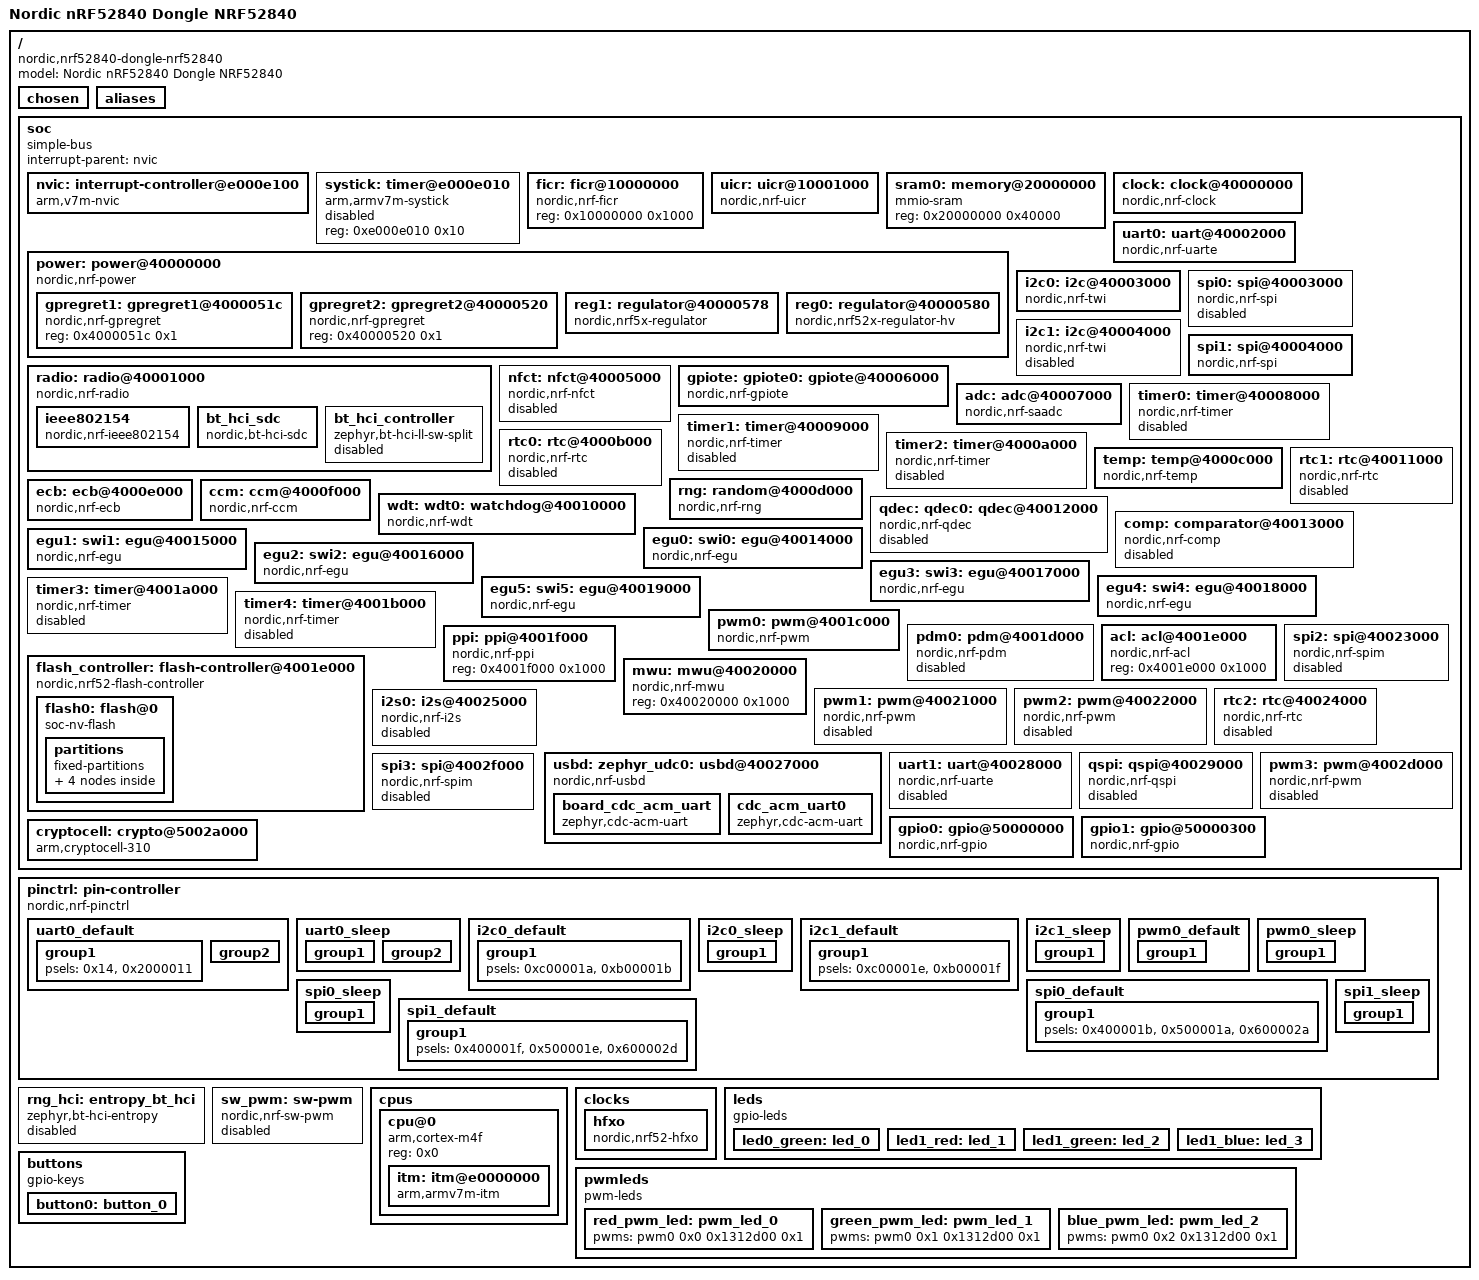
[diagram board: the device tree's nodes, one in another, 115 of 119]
/dts-v1/;

/* node '/' defined in zephyr\dts\common\skeleton.dtsi:9 */
/ {
	#address-cells = < 0x1 >;                       /* in zephyr\dts\common\skeleton.dtsi:10 */
	#size-cells = < 0x1 >;                          /* in zephyr\dts\common\skeleton.dtsi:11 */
	model = "Nordic nRF52840 Dongle NRF52840";      /* in zephyr\boards\nordic\nrf52840dongle\nrf52840dongle_nrf52840_common.dtsi:14 */
	compatible = "nordic,nrf52840-dongle-nrf52840"; /* in zephyr\boards\nordic\nrf52840dongle\nrf52840dongle_nrf52840_common.dtsi:15 */

	/* node '/chosen' defined in zephyr\dts\common\skeleton.dtsi:13 */
	chosen {
		zephyr,bt-hci = &bt_hci_sdc;                 /* in zephyr\dts\arm\nordic\nrf52840.dtsi:14 */
		zephyr,entropy = &cryptocell;                /* in zephyr\dts\arm\nordic\nrf52840.dtsi:15 */
		zephyr,flash-controller = &flash_controller; /* in zephyr\dts\arm\nordic\nrf52840.dtsi:16 */
		zephyr,sram = &sram0;                        /* in zephyr\boards\nordic\nrf52840dongle\nrf52840dongle_nrf52840_common.dtsi:18 */
		zephyr,flash = &flash0;                      /* in zephyr\boards\nordic\nrf52840dongle\nrf52840dongle_nrf52840_common.dtsi:19 */
		zephyr,code-partition = &slot0_partition;    /* in zephyr\boards\nordic\nrf52840dongle\nrf52840dongle_nrf52840_common.dtsi:20 */
		zephyr,ieee802154 = &ieee802154;             /* in zephyr\boards\nordic\nrf52840dongle\nrf52840dongle_nrf52840_common.dtsi:21 */
		zephyr,uart-mcumgr = &board_cdc_acm_uart;    /* in zephyr\boards\common\usb\cdc_acm_serial.dtsi:11 */
		zephyr,bt-mon-uart = &board_cdc_acm_uart;    /* in zephyr\boards\common\usb\cdc_acm_serial.dtsi:12 */
		zephyr,bt-c2h-uart = &board_cdc_acm_uart;    /* in zephyr\boards\common\usb\cdc_acm_serial.dtsi:13 */
		zephyr,console = &cdc_acm_uart0;             /* in nrf\samples\bluetooth\central_uart_test\app.overlay:3 */
		zephyr,shell-uart = &cdc_acm_uart0;          /* in nrf\samples\bluetooth\central_uart_test\app.overlay:4 */
	};

	/* node '/aliases' defined in zephyr\dts\common\skeleton.dtsi:15 */
	aliases {
		sw0 = &button0;                 /* in zephyr\boards\nordic\nrf52840dongle\nrf52840dongle_nrf52840_common.dtsi:76 */
		led0 = &led0_green;             /* in zephyr\boards\nordic\nrf52840dongle\nrf52840dongle_nrf52840_common.dtsi:77 */
		led1 = &led1_red;               /* in zephyr\boards\nordic\nrf52840dongle\nrf52840dongle_nrf52840_common.dtsi:78 */
		led2 = &led1_green;             /* in zephyr\boards\nordic\nrf52840dongle\nrf52840dongle_nrf52840_common.dtsi:79 */
		led3 = &led1_blue;              /* in zephyr\boards\nordic\nrf52840dongle\nrf52840dongle_nrf52840_common.dtsi:80 */
		led0-green = &led0_green;       /* in zephyr\boards\nordic\nrf52840dongle\nrf52840dongle_nrf52840_common.dtsi:81 */
		led1-red = &led1_red;           /* in zephyr\boards\nordic\nrf52840dongle\nrf52840dongle_nrf52840_common.dtsi:82 */
		led1-green = &led1_green;       /* in zephyr\boards\nordic\nrf52840dongle\nrf52840dongle_nrf52840_common.dtsi:83 */
		led1-blue = &led1_blue;         /* in zephyr\boards\nordic\nrf52840dongle\nrf52840dongle_nrf52840_common.dtsi:84 */
		pwm-led0 = &red_pwm_led;        /* in zephyr\boards\nordic\nrf52840dongle\nrf52840dongle_nrf52840_common.dtsi:85 */
		pwm-led1 = &green_pwm_led;      /* in zephyr\boards\nordic\nrf52840dongle\nrf52840dongle_nrf52840_common.dtsi:86 */
		pwm-led2 = &blue_pwm_led;       /* in zephyr\boards\nordic\nrf52840dongle\nrf52840dongle_nrf52840_common.dtsi:87 */
		red-pwm-led = &red_pwm_led;     /* in zephyr\boards\nordic\nrf52840dongle\nrf52840dongle_nrf52840_common.dtsi:88 */
		green-pwm-led = &green_pwm_led; /* in zephyr\boards\nordic\nrf52840dongle\nrf52840dongle_nrf52840_common.dtsi:89 */
		blue-pwm-led = &blue_pwm_led;   /* in zephyr\boards\nordic\nrf52840dongle\nrf52840dongle_nrf52840_common.dtsi:90 */
		mcuboot-button0 = &button0;     /* in zephyr\boards\nordic\nrf52840dongle\nrf52840dongle_nrf52840_common.dtsi:91 */
		mcuboot-led0 = &led0_green;     /* in zephyr\boards\nordic\nrf52840dongle\nrf52840dongle_nrf52840_common.dtsi:92 */
		watchdog0 = &wdt0;              /* in zephyr\boards\nordic\nrf52840dongle\nrf52840dongle_nrf52840_common.dtsi:93 */
	};

	/* node '/soc' defined in zephyr\dts\arm\armv7-m.dtsi:6 */
	soc {
		#address-cells = < 0x1 >;     /* in zephyr\dts\arm\armv7-m.dtsi:7 */
		#size-cells = < 0x1 >;        /* in zephyr\dts\arm\armv7-m.dtsi:8 */
		interrupt-parent = < &nvic >; /* in zephyr\dts\arm\armv7-m.dtsi:10 */
		ranges;                       /* in zephyr\dts\arm\armv7-m.dtsi:11 */
		compatible = "simple-bus";    /* in zephyr\dts\arm\nordic\nrf52840_qiaa.dtsi:30 */

		/* node '/soc/interrupt-controller@e000e100' defined in zephyr\dts\arm\armv7-m.dtsi:13 */
		nvic: interrupt-controller@e000e100 {
			#address-cells = < 0x1 >;            /* in zephyr\dts\arm\armv7-m.dtsi:14 */
			compatible = "arm,v7m-nvic";         /* in zephyr\dts\arm\armv7-m.dtsi:15 */
			reg = < 0xe000e100 0xc00 >;          /* in zephyr\dts\arm\armv7-m.dtsi:16 */
			interrupt-controller;                /* in zephyr\dts\arm\armv7-m.dtsi:17 */
			#interrupt-cells = < 0x2 >;          /* in zephyr\dts\arm\armv7-m.dtsi:18 */
			arm,num-irq-priority-bits = < 0x3 >; /* in zephyr\dts\arm\nordic\nrf52840.dtsi:590 */
			phandle = < 0x1 >;                   /* in zephyr\dts\arm\armv7-m.dtsi:10 */
		};

		/* node '/soc/timer@e000e010' defined in zephyr\dts\arm\armv7-m.dtsi:21 */
		systick: timer@e000e010 {
			compatible = "arm,armv7m-systick"; /* in zephyr\dts\arm\armv7-m.dtsi:22 */
			reg = < 0xe000e010 0x10 >;         /* in zephyr\dts\arm\armv7-m.dtsi:23 */
			status = "disabled";               /* in zephyr\dts\arm\nordic\nrf52840.dtsi:595 */
		};

		/* node '/soc/ficr@10000000' defined in zephyr\dts\arm\nordic\nrf52840.dtsi:48 */
		ficr: ficr@10000000 {
			compatible = "nordic,nrf-ficr"; /* in zephyr\dts\arm\nordic\nrf52840.dtsi:49 */
			reg = < 0x10000000 0x1000 >;    /* in zephyr\dts\arm\nordic\nrf52840.dtsi:50 */
			#nordic,ficr-cells = < 0x1 >;   /* in zephyr\dts\arm\nordic\nrf52840.dtsi:51 */
			status = "okay";                /* in zephyr\dts\arm\nordic\nrf52840.dtsi:52 */
		};

		/* node '/soc/uicr@10001000' defined in zephyr\dts\arm\nordic\nrf52840.dtsi:55 */
		uicr: uicr@10001000 {
			compatible = "nordic,nrf-uicr";     /* in zephyr\dts\arm\nordic\nrf52840.dtsi:56 */
			reg = < 0x10001000 0x1000 >;        /* in zephyr\dts\arm\nordic\nrf52840.dtsi:57 */
			ranges = < 0x0 0x10001000 0x1000 >; /* in zephyr\dts\arm\nordic\nrf52840.dtsi:58 */
			status = "okay";                    /* in zephyr\dts\arm\nordic\nrf52840.dtsi:59 */
			#address-cells = < 0x1 >;           /* in zephyr\dts\arm\nordic\nrf52840.dtsi:60 */
			#size-cells = < 0x1 >;              /* in zephyr\dts\arm\nordic\nrf52840.dtsi:61 */
			nfct-pins-as-gpios;                 /* in zephyr\boards\nordic\nrf52840dongle\nrf52840dongle_nrf52840_common.dtsi:114 */
			gpio-as-nreset;                     /* in zephyr\boards\nordic\nrf52840dongle\nrf52840dongle_nrf52840_common.dtsi:115 */
		};

		/* node '/soc/memory@20000000' defined in zephyr\dts\arm\nordic\nrf52840.dtsi:64 */
		sram0: memory@20000000 {
			compatible = "mmio-sram";            /* in zephyr\dts\arm\nordic\nrf52840.dtsi:65 */
			#address-cells = < 0x1 >;            /* in zephyr\dts\arm\nordic\nrf52840.dtsi:66 */
			#size-cells = < 0x1 >;               /* in zephyr\dts\arm\nordic\nrf52840.dtsi:67 */
			reg = < 0x20000000 0x40000 >;        /* in zephyr\dts\arm\nordic\nrf52840_qiaa.dtsi:15 */
			ranges = < 0x0 0x20000000 0x40000 >; /* in zephyr\dts\arm\nordic\nrf52840_qiaa.dtsi:16 */
		};

		/* node '/soc/clock@40000000' defined in zephyr\dts\arm\nordic\nrf52840.dtsi:70 */
		clock: clock@40000000 {
			compatible = "nordic,nrf-clock"; /* in zephyr\dts\arm\nordic\nrf52840.dtsi:71 */
			reg = < 0x40000000 0x1000 >;     /* in zephyr\dts\arm\nordic\nrf52840.dtsi:72 */
			interrupts = < 0x0 0x1 >;        /* in zephyr\dts\arm\nordic\nrf52840.dtsi:73 */
			status = "okay";                 /* in zephyr\dts\arm\nordic\nrf52840.dtsi:74 */
		};

		/* node '/soc/power@40000000' defined in zephyr\dts\arm\nordic\nrf52840.dtsi:77 */
		power: power@40000000 {
			compatible = "nordic,nrf-power"; /* in zephyr\dts\arm\nordic\nrf52840.dtsi:78 */
			reg = < 0x40000000 0x1000 >;     /* in zephyr\dts\arm\nordic\nrf52840.dtsi:79 */
			interrupts = < 0x0 0x1 >;        /* in zephyr\dts\arm\nordic\nrf52840.dtsi:80 */
			status = "okay";                 /* in zephyr\dts\arm\nordic\nrf52840.dtsi:81 */
			#address-cells = < 0x1 >;        /* in zephyr\dts\arm\nordic\nrf52840.dtsi:82 */
			#size-cells = < 0x1 >;           /* in zephyr\dts\arm\nordic\nrf52840.dtsi:83 */

			/* node '/soc/power@40000000/gpregret1@4000051c' defined in zephyr\dts\arm\nordic\nrf52840.dtsi:85 */
			gpregret1: gpregret1@4000051c {
				#address-cells = < 0x1 >;           /* in zephyr\dts\arm\nordic\nrf52840.dtsi:86 */
				#size-cells = < 0x1 >;              /* in zephyr\dts\arm\nordic\nrf52840.dtsi:87 */
				compatible = "nordic,nrf-gpregret"; /* in zephyr\dts\arm\nordic\nrf52840.dtsi:88 */
				reg = < 0x4000051c 0x1 >;           /* in zephyr\dts\arm\nordic\nrf52840.dtsi:89 */
				status = "okay";                    /* in zephyr\dts\arm\nordic\nrf52840.dtsi:90 */
			};

			/* node '/soc/power@40000000/gpregret2@40000520' defined in zephyr\dts\arm\nordic\nrf52840.dtsi:93 */
			gpregret2: gpregret2@40000520 {
				#address-cells = < 0x1 >;           /* in zephyr\dts\arm\nordic\nrf52840.dtsi:94 */
				#size-cells = < 0x1 >;              /* in zephyr\dts\arm\nordic\nrf52840.dtsi:95 */
				compatible = "nordic,nrf-gpregret"; /* in zephyr\dts\arm\nordic\nrf52840.dtsi:96 */
				reg = < 0x40000520 0x1 >;           /* in zephyr\dts\arm\nordic\nrf52840.dtsi:97 */
				status = "okay";                    /* in zephyr\dts\arm\nordic\nrf52840.dtsi:98 */
			};

			/* node '/soc/power@40000000/regulator@40000578' defined in zephyr\dts\arm\nordic\nrf52840.dtsi:101 */
			reg1: regulator@40000578 {
				compatible = "nordic,nrf5x-regulator"; /* in zephyr\dts\arm\nordic\nrf52840.dtsi:102 */
				reg = < 0x40000578 0x1 >;              /* in zephyr\dts\arm\nordic\nrf52840.dtsi:103 */
				regulator-name = "REG1";               /* in zephyr\dts\arm\nordic\nrf52840.dtsi:104 */
				regulator-initial-mode = < 0x1 >;      /* in zephyr\boards\nordic\nrf52840dongle\nrf52840dongle_nrf52840_common.dtsi:102 */
			};

			/* node '/soc/power@40000000/regulator@40000580' defined in zephyr\dts\arm\nordic\nrf52840_qiaa.dtsi:20 */
			reg0: regulator@40000580 {
				compatible = "nordic,nrf52x-regulator-hv"; /* in zephyr\dts\arm\nordic\nrf52840_qiaa.dtsi:21 */
				reg = < 0x40000580 0x1 >;                  /* in zephyr\dts\arm\nordic\nrf52840_qiaa.dtsi:22 */
				regulator-name = "REG0";                   /* in zephyr\dts\arm\nordic\nrf52840_qiaa.dtsi:23 */
				status = "okay";                           /* in zephyr\boards\nordic\nrf52840dongle\nrf52840dongle_nrf52840_common.dtsi:98 */
			};
		};

		/* node '/soc/radio@40001000' defined in zephyr\dts\arm\nordic\nrf52840.dtsi:109 */
		radio: radio@40001000 {
			compatible = "nordic,nrf-radio"; /* in zephyr\dts\arm\nordic\nrf52840.dtsi:110 */
			reg = < 0x40001000 0x1000 >;     /* in zephyr\dts\arm\nordic\nrf52840.dtsi:111 */
			interrupts = < 0x1 0x1 >;        /* in zephyr\dts\arm\nordic\nrf52840.dtsi:112 */
			status = "okay";                 /* in zephyr\dts\arm\nordic\nrf52840.dtsi:113 */
			ieee802154-supported;            /* in zephyr\dts\arm\nordic\nrf52840.dtsi:114 */
			ble-2mbps-supported;             /* in zephyr\dts\arm\nordic\nrf52840.dtsi:115 */
			ble-coded-phy-supported;         /* in zephyr\dts\arm\nordic\nrf52840.dtsi:116 */
			radio-tx-high-power-supported;   /* in zephyr\dts\arm\nordic\nrf52840.dtsi:117 */

			/* node '/soc/radio@40001000/ieee802154' defined in zephyr\dts\arm\nordic\nrf52840.dtsi:119 */
			ieee802154: ieee802154 {
				compatible = "nordic,nrf-ieee802154"; /* in zephyr\dts\arm\nordic\nrf52840.dtsi:120 */
				status = "okay";                      /* in zephyr\boards\nordic\nrf52840dongle\nrf52840dongle_nrf52840_common.dtsi:181 */
			};

			/* node '/soc/radio@40001000/bt_hci_sdc' defined in zephyr\dts\arm\nordic\nrf52840.dtsi:124 */
			bt_hci_sdc: bt_hci_sdc {
				compatible = "nordic,bt-hci-sdc"; /* in zephyr\dts\arm\nordic\nrf52840.dtsi:125 */
				status = "okay";                  /* in zephyr\dts\arm\nordic\nrf52840.dtsi:126 */
			};

			/* node '/soc/radio@40001000/bt_hci_controller' defined in zephyr\dts\arm\nordic\nrf52840.dtsi:128 */
			bt_hci_controller: bt_hci_controller {
				compatible = "zephyr,bt-hci-ll-sw-split"; /* in zephyr\dts\arm\nordic\nrf52840.dtsi:129 */
				status = "disabled";                      /* in zephyr\dts\arm\nordic\nrf52840.dtsi:130 */
			};
		};

		/* node '/soc/uart@40002000' defined in zephyr\dts\arm\nordic\nrf52840.dtsi:134 */
		uart0: uart@40002000 {
			reg = < 0x40002000 0x1000 >;     /* in zephyr\dts\arm\nordic\nrf52840.dtsi:138 */
			interrupts = < 0x2 0x1 >;        /* in zephyr\dts\arm\nordic\nrf52840.dtsi:139 */
			compatible = "nordic,nrf-uarte"; /* in zephyr\boards\nordic\nrf52840dongle\nrf52840dongle_nrf52840_common.dtsi:127 */
			status = "okay";                 /* in zephyr\boards\nordic\nrf52840dongle\nrf52840dongle_nrf52840_common.dtsi:128 */
			current-speed = < 0x1c200 >;     /* in zephyr\boards\nordic\nrf52840dongle\nrf52840dongle_nrf52840_common.dtsi:129 */
			pinctrl-0 = < &uart0_default >;  /* in zephyr\boards\nordic\nrf52840dongle\nrf52840dongle_nrf52840_common.dtsi:130 */
			pinctrl-1 = < &uart0_sleep >;    /* in zephyr\boards\nordic\nrf52840dongle\nrf52840dongle_nrf52840_common.dtsi:131 */
			pinctrl-names = "default",
			                "sleep";         /* in zephyr\boards\nordic\nrf52840dongle\nrf52840dongle_nrf52840_common.dtsi:132 */
		};

		/* node '/soc/i2c@40003000' defined in zephyr\dts\arm\nordic\nrf52840.dtsi:143 */
		i2c0: i2c@40003000 {
			#address-cells = < 0x1 >;       /* in zephyr\dts\arm\nordic\nrf52840.dtsi:152 */
			#size-cells = < 0x0 >;          /* in zephyr\dts\arm\nordic\nrf52840.dtsi:153 */
			reg = < 0x40003000 0x1000 >;    /* in zephyr\dts\arm\nordic\nrf52840.dtsi:154 */
			interrupts = < 0x3 0x1 >;       /* in zephyr\dts\arm\nordic\nrf52840.dtsi:155 */
			easydma-maxcnt-bits = < 0x10 >; /* in zephyr\dts\arm\nordic\nrf52840.dtsi:156 */
			zephyr,pm-device-runtime-auto;  /* in zephyr\dts\arm\nordic\nrf52840.dtsi:158 */
			compatible = "nordic,nrf-twi";  /* in zephyr\boards\nordic\nrf52840dongle\nrf52840dongle_nrf52840_common.dtsi:136 */
			status = "okay";                /* in zephyr\boards\nordic\nrf52840dongle\nrf52840dongle_nrf52840_common.dtsi:137 */
			pinctrl-0 = < &i2c0_default >;  /* in zephyr\boards\nordic\nrf52840dongle\nrf52840dongle_nrf52840_common.dtsi:138 */
			pinctrl-1 = < &i2c0_sleep >;    /* in zephyr\boards\nordic\nrf52840dongle\nrf52840dongle_nrf52840_common.dtsi:139 */
			pinctrl-names = "default",
			                "sleep";        /* in zephyr\boards\nordic\nrf52840dongle\nrf52840dongle_nrf52840_common.dtsi:140 */
		};

		/* node '/soc/spi@40003000' defined in zephyr\dts\arm\nordic\nrf52840.dtsi:161 */
		spi0: spi@40003000 {
			#address-cells = < 0x1 >;       /* in zephyr\dts\arm\nordic\nrf52840.dtsi:170 */
			#size-cells = < 0x0 >;          /* in zephyr\dts\arm\nordic\nrf52840.dtsi:171 */
			reg = < 0x40003000 0x1000 >;    /* in zephyr\dts\arm\nordic\nrf52840.dtsi:172 */
			interrupts = < 0x3 0x1 >;       /* in zephyr\dts\arm\nordic\nrf52840.dtsi:173 */
			max-frequency = < 0x7a1200 >;   /* in zephyr\dts\arm\nordic\nrf52840.dtsi:174 */
			easydma-maxcnt-bits = < 0x10 >; /* in zephyr\dts\arm\nordic\nrf52840.dtsi:175 */
			status = "disabled";            /* in zephyr\dts\arm\nordic\nrf52840.dtsi:176 */
			compatible = "nordic,nrf-spi";  /* in zephyr\boards\nordic\nrf52840dongle\nrf52840dongle_nrf52840_common.dtsi:164 */
			pinctrl-0 = < &spi0_default >;  /* in zephyr\boards\nordic\nrf52840dongle\nrf52840dongle_nrf52840_common.dtsi:167 */
			pinctrl-1 = < &spi0_sleep >;    /* in zephyr\boards\nordic\nrf52840dongle\nrf52840dongle_nrf52840_common.dtsi:168 */
			pinctrl-names = "default",
			                "sleep";        /* in zephyr\boards\nordic\nrf52840dongle\nrf52840dongle_nrf52840_common.dtsi:169 */
		};

		/* node '/soc/i2c@40004000' defined in zephyr\dts\arm\nordic\nrf52840.dtsi:179 */
		i2c1: i2c@40004000 {
			#address-cells = < 0x1 >;       /* in zephyr\dts\arm\nordic\nrf52840.dtsi:188 */
			#size-cells = < 0x0 >;          /* in zephyr\dts\arm\nordic\nrf52840.dtsi:189 */
			reg = < 0x40004000 0x1000 >;    /* in zephyr\dts\arm\nordic\nrf52840.dtsi:190 */
			interrupts = < 0x4 0x1 >;       /* in zephyr\dts\arm\nordic\nrf52840.dtsi:191 */
			easydma-maxcnt-bits = < 0x10 >; /* in zephyr\dts\arm\nordic\nrf52840.dtsi:192 */
			status = "disabled";            /* in zephyr\dts\arm\nordic\nrf52840.dtsi:193 */
			zephyr,pm-device-runtime-auto;  /* in zephyr\dts\arm\nordic\nrf52840.dtsi:194 */
			compatible = "nordic,nrf-twi";  /* in zephyr\boards\nordic\nrf52840dongle\nrf52840dongle_nrf52840_common.dtsi:144 */
			pinctrl-0 = < &i2c1_default >;  /* in zephyr\boards\nordic\nrf52840dongle\nrf52840dongle_nrf52840_common.dtsi:147 */
			pinctrl-1 = < &i2c1_sleep >;    /* in zephyr\boards\nordic\nrf52840dongle\nrf52840dongle_nrf52840_common.dtsi:148 */
			pinctrl-names = "default",
			                "sleep";        /* in zephyr\boards\nordic\nrf52840dongle\nrf52840dongle_nrf52840_common.dtsi:149 */
		};

		/* node '/soc/spi@40004000' defined in zephyr\dts\arm\nordic\nrf52840.dtsi:197 */
		spi1: spi@40004000 {
			#address-cells = < 0x1 >;       /* in zephyr\dts\arm\nordic\nrf52840.dtsi:206 */
			#size-cells = < 0x0 >;          /* in zephyr\dts\arm\nordic\nrf52840.dtsi:207 */
			reg = < 0x40004000 0x1000 >;    /* in zephyr\dts\arm\nordic\nrf52840.dtsi:208 */
			interrupts = < 0x4 0x1 >;       /* in zephyr\dts\arm\nordic\nrf52840.dtsi:209 */
			max-frequency = < 0x7a1200 >;   /* in zephyr\dts\arm\nordic\nrf52840.dtsi:210 */
			easydma-maxcnt-bits = < 0x10 >; /* in zephyr\dts\arm\nordic\nrf52840.dtsi:211 */
			compatible = "nordic,nrf-spi";  /* in zephyr\boards\nordic\nrf52840dongle\nrf52840dongle_nrf52840_common.dtsi:173 */
			status = "okay";                /* in zephyr\boards\nordic\nrf52840dongle\nrf52840dongle_nrf52840_common.dtsi:174 */
			pinctrl-0 = < &spi1_default >;  /* in zephyr\boards\nordic\nrf52840dongle\nrf52840dongle_nrf52840_common.dtsi:175 */
			pinctrl-1 = < &spi1_sleep >;    /* in zephyr\boards\nordic\nrf52840dongle\nrf52840dongle_nrf52840_common.dtsi:176 */
			pinctrl-names = "default",
			                "sleep";        /* in zephyr\boards\nordic\nrf52840dongle\nrf52840dongle_nrf52840_common.dtsi:177 */
		};

		/* node '/soc/nfct@40005000' defined in zephyr\dts\arm\nordic\nrf52840.dtsi:215 */
		nfct: nfct@40005000 {
			compatible = "nordic,nrf-nfct"; /* in zephyr\dts\arm\nordic\nrf52840.dtsi:216 */
			reg = < 0x40005000 0x1000 >;    /* in zephyr\dts\arm\nordic\nrf52840.dtsi:217 */
			interrupts = < 0x5 0x1 >;       /* in zephyr\dts\arm\nordic\nrf52840.dtsi:218 */
			status = "disabled";            /* in zephyr\dts\arm\nordic\nrf52840.dtsi:219 */
		};

		/* node '/soc/gpiote@40006000' defined in zephyr\dts\arm\nordic\nrf52840.dtsi:222 */
		gpiote: gpiote0: gpiote@40006000 {
			compatible = "nordic,nrf-gpiote"; /* in zephyr\dts\arm\nordic\nrf52840.dtsi:223 */
			reg = < 0x40006000 0x1000 >;      /* in zephyr\dts\arm\nordic\nrf52840.dtsi:224 */
			interrupts = < 0x6 0x5 >;         /* in zephyr\dts\arm\nordic\nrf52840.dtsi:225 */
			instance = < 0x0 >;               /* in zephyr\dts\arm\nordic\nrf52840.dtsi:227 */
			status = "okay";                  /* in zephyr\boards\nordic\nrf52840dongle\nrf52840dongle_nrf52840_common.dtsi:110 */
			phandle = < 0xe >;                /* in zephyr\dts\arm\nordic\nrf52840.dtsi:564 */
		};

		/* node '/soc/adc@40007000' defined in zephyr\dts\arm\nordic\nrf52840.dtsi:230 */
		adc: adc@40007000 {
			compatible = "nordic,nrf-saadc"; /* in zephyr\dts\arm\nordic\nrf52840.dtsi:231 */
			reg = < 0x40007000 0x1000 >;     /* in zephyr\dts\arm\nordic\nrf52840.dtsi:232 */
			interrupts = < 0x7 0x1 >;        /* in zephyr\dts\arm\nordic\nrf52840.dtsi:233 */
			#io-channel-cells = < 0x1 >;     /* in zephyr\dts\arm\nordic\nrf52840.dtsi:235 */
			zephyr,pm-device-runtime-auto;   /* in zephyr\dts\arm\nordic\nrf52840.dtsi:236 */
			status = "okay";                 /* in zephyr\boards\nordic\nrf52840dongle\nrf52840dongle_nrf52840_common.dtsi:106 */
		};

		/* node '/soc/timer@40008000' defined in zephyr\dts\arm\nordic\nrf52840.dtsi:239 */
		timer0: timer@40008000 {
			compatible = "nordic,nrf-timer"; /* in zephyr\dts\arm\nordic\nrf52840.dtsi:240 */
			status = "disabled";             /* in zephyr\dts\arm\nordic\nrf52840.dtsi:241 */
			reg = < 0x40008000 0x1000 >;     /* in zephyr\dts\arm\nordic\nrf52840.dtsi:242 */
			cc-num = < 0x4 >;                /* in zephyr\dts\arm\nordic\nrf52840.dtsi:243 */
			max-bit-width = < 0x20 >;        /* in zephyr\dts\arm\nordic\nrf52840.dtsi:244 */
			interrupts = < 0x8 0x1 >;        /* in zephyr\dts\arm\nordic\nrf52840.dtsi:245 */
			prescaler = < 0x0 >;             /* in zephyr\dts\arm\nordic\nrf52840.dtsi:246 */
		};

		/* node '/soc/timer@40009000' defined in zephyr\dts\arm\nordic\nrf52840.dtsi:249 */
		timer1: timer@40009000 {
			compatible = "nordic,nrf-timer"; /* in zephyr\dts\arm\nordic\nrf52840.dtsi:250 */
			status = "disabled";             /* in zephyr\dts\arm\nordic\nrf52840.dtsi:251 */
			reg = < 0x40009000 0x1000 >;     /* in zephyr\dts\arm\nordic\nrf52840.dtsi:252 */
			cc-num = < 0x4 >;                /* in zephyr\dts\arm\nordic\nrf52840.dtsi:253 */
			max-bit-width = < 0x20 >;        /* in zephyr\dts\arm\nordic\nrf52840.dtsi:254 */
			interrupts = < 0x9 0x1 >;        /* in zephyr\dts\arm\nordic\nrf52840.dtsi:255 */
			prescaler = < 0x0 >;             /* in zephyr\dts\arm\nordic\nrf52840.dtsi:256 */
			phandle = < 0xf >;               /* in zephyr\dts\vendor\nordic\nrf_common.dtsi:42 */
		};

		/* node '/soc/timer@4000a000' defined in zephyr\dts\arm\nordic\nrf52840.dtsi:259 */
		timer2: timer@4000a000 {
			compatible = "nordic,nrf-timer"; /* in zephyr\dts\arm\nordic\nrf52840.dtsi:260 */
			status = "disabled";             /* in zephyr\dts\arm\nordic\nrf52840.dtsi:261 */
			reg = < 0x4000a000 0x1000 >;     /* in zephyr\dts\arm\nordic\nrf52840.dtsi:262 */
			cc-num = < 0x4 >;                /* in zephyr\dts\arm\nordic\nrf52840.dtsi:263 */
			max-bit-width = < 0x20 >;        /* in zephyr\dts\arm\nordic\nrf52840.dtsi:264 */
			interrupts = < 0xa 0x1 >;        /* in zephyr\dts\arm\nordic\nrf52840.dtsi:265 */
			prescaler = < 0x0 >;             /* in zephyr\dts\arm\nordic\nrf52840.dtsi:266 */
		};

		/* node '/soc/rtc@4000b000' defined in zephyr\dts\arm\nordic\nrf52840.dtsi:269 */
		rtc0: rtc@4000b000 {
			compatible = "nordic,nrf-rtc"; /* in zephyr\dts\arm\nordic\nrf52840.dtsi:270 */
			reg = < 0x4000b000 0x1000 >;   /* in zephyr\dts\arm\nordic\nrf52840.dtsi:271 */
			cc-num = < 0x3 >;              /* in zephyr\dts\arm\nordic\nrf52840.dtsi:272 */
			interrupts = < 0xb 0x1 >;      /* in zephyr\dts\arm\nordic\nrf52840.dtsi:273 */
			status = "disabled";           /* in zephyr\dts\arm\nordic\nrf52840.dtsi:274 */
			clock-frequency = < 0x8000 >;  /* in zephyr\dts\arm\nordic\nrf52840.dtsi:275 */
			prescaler = < 0x1 >;           /* in zephyr\dts\arm\nordic\nrf52840.dtsi:276 */
		};

		/* node '/soc/temp@4000c000' defined in zephyr\dts\arm\nordic\nrf52840.dtsi:279 */
		temp: temp@4000c000 {
			compatible = "nordic,nrf-temp"; /* in zephyr\dts\arm\nordic\nrf52840.dtsi:280 */
			reg = < 0x4000c000 0x1000 >;    /* in zephyr\dts\arm\nordic\nrf52840.dtsi:281 */
			interrupts = < 0xc 0x1 >;       /* in zephyr\dts\arm\nordic\nrf52840.dtsi:282 */
			status = "okay";                /* in zephyr\dts\arm\nordic\nrf52840.dtsi:283 */
		};

		/* node '/soc/random@4000d000' defined in zephyr\dts\arm\nordic\nrf52840.dtsi:286 */
		rng: random@4000d000 {
			compatible = "nordic,nrf-rng"; /* in zephyr\dts\arm\nordic\nrf52840.dtsi:287 */
			reg = < 0x4000d000 0x1000 >;   /* in zephyr\dts\arm\nordic\nrf52840.dtsi:288 */
			interrupts = < 0xd 0x1 >;      /* in zephyr\dts\arm\nordic\nrf52840.dtsi:289 */
			status = "okay";               /* in zephyr\dts\arm\nordic\nrf52840.dtsi:290 */
		};

		/* node '/soc/ecb@4000e000' defined in zephyr\dts\arm\nordic\nrf52840.dtsi:293 */
		ecb: ecb@4000e000 {
			compatible = "nordic,nrf-ecb"; /* in zephyr\dts\arm\nordic\nrf52840.dtsi:294 */
			reg = < 0x4000e000 0x1000 >;   /* in zephyr\dts\arm\nordic\nrf52840.dtsi:295 */
			interrupts = < 0xe 0x1 >;      /* in zephyr\dts\arm\nordic\nrf52840.dtsi:296 */
			status = "okay";               /* in zephyr\dts\arm\nordic\nrf52840.dtsi:297 */
		};

		/* node '/soc/ccm@4000f000' defined in zephyr\dts\arm\nordic\nrf52840.dtsi:300 */
		ccm: ccm@4000f000 {
			compatible = "nordic,nrf-ccm"; /* in zephyr\dts\arm\nordic\nrf52840.dtsi:301 */
			reg = < 0x4000f000 0x1000 >;   /* in zephyr\dts\arm\nordic\nrf52840.dtsi:302 */
			interrupts = < 0xf 0x1 >;      /* in zephyr\dts\arm\nordic\nrf52840.dtsi:303 */
			length-field-length-8-bits;    /* in zephyr\dts\arm\nordic\nrf52840.dtsi:304 */
			status = "okay";               /* in zephyr\dts\arm\nordic\nrf52840.dtsi:305 */
		};

		/* node '/soc/watchdog@40010000' defined in zephyr\dts\arm\nordic\nrf52840.dtsi:308 */
		wdt: wdt0: watchdog@40010000 {
			compatible = "nordic,nrf-wdt"; /* in zephyr\dts\arm\nordic\nrf52840.dtsi:309 */
			reg = < 0x40010000 0x1000 >;   /* in zephyr\dts\arm\nordic\nrf52840.dtsi:310 */
			interrupts = < 0x10 0x1 >;     /* in zephyr\dts\arm\nordic\nrf52840.dtsi:311 */
			status = "okay";               /* in zephyr\dts\arm\nordic\nrf52840.dtsi:312 */
		};

		/* node '/soc/rtc@40011000' defined in zephyr\dts\arm\nordic\nrf52840.dtsi:315 */
		rtc1: rtc@40011000 {
			compatible = "nordic,nrf-rtc"; /* in zephyr\dts\arm\nordic\nrf52840.dtsi:316 */
			reg = < 0x40011000 0x1000 >;   /* in zephyr\dts\arm\nordic\nrf52840.dtsi:317 */
			cc-num = < 0x4 >;              /* in zephyr\dts\arm\nordic\nrf52840.dtsi:318 */
			interrupts = < 0x11 0x1 >;     /* in zephyr\dts\arm\nordic\nrf52840.dtsi:319 */
			status = "disabled";           /* in zephyr\dts\arm\nordic\nrf52840.dtsi:320 */
			clock-frequency = < 0x8000 >;  /* in zephyr\dts\arm\nordic\nrf52840.dtsi:321 */
			prescaler = < 0x1 >;           /* in zephyr\dts\arm\nordic\nrf52840.dtsi:322 */
		};

		/* node '/soc/qdec@40012000' defined in zephyr\dts\arm\nordic\nrf52840.dtsi:325 */
		qdec: qdec0: qdec@40012000 {
			compatible = "nordic,nrf-qdec"; /* in zephyr\dts\arm\nordic\nrf52840.dtsi:326 */
			reg = < 0x40012000 0x1000 >;    /* in zephyr\dts\arm\nordic\nrf52840.dtsi:327 */
			interrupts = < 0x12 0x1 >;      /* in zephyr\dts\arm\nordic\nrf52840.dtsi:328 */
			status = "disabled";            /* in zephyr\dts\arm\nordic\nrf52840.dtsi:329 */
		};

		/* node '/soc/comparator@40013000' defined in zephyr\dts\arm\nordic\nrf52840.dtsi:332 */
		comp: comparator@40013000 {
			compatible = "nordic,nrf-comp"; /* in zephyr\dts\arm\nordic\nrf52840.dtsi:337 */
			reg = < 0x40013000 0x1000 >;    /* in zephyr\dts\arm\nordic\nrf52840.dtsi:338 */
			interrupts = < 0x13 0x1 >;      /* in zephyr\dts\arm\nordic\nrf52840.dtsi:339 */
			status = "disabled";            /* in zephyr\dts\arm\nordic\nrf52840.dtsi:340 */
		};

		/* node '/soc/egu@40014000' defined in zephyr\dts\arm\nordic\nrf52840.dtsi:343 */
		egu0: swi0: egu@40014000 {
			compatible = "nordic,nrf-egu",
			             "nordic,nrf-swi"; /* in zephyr\dts\arm\nordic\nrf52840.dtsi:344 */
			reg = < 0x40014000 0x1000 >;   /* in zephyr\dts\arm\nordic\nrf52840.dtsi:345 */
			interrupts = < 0x14 0x1 >;     /* in zephyr\dts\arm\nordic\nrf52840.dtsi:346 */
			status = "okay";               /* in zephyr\dts\arm\nordic\nrf52840.dtsi:347 */
		};

		/* node '/soc/egu@40015000' defined in zephyr\dts\arm\nordic\nrf52840.dtsi:350 */
		egu1: swi1: egu@40015000 {
			compatible = "nordic,nrf-egu",
			             "nordic,nrf-swi"; /* in zephyr\dts\arm\nordic\nrf52840.dtsi:351 */
			reg = < 0x40015000 0x1000 >;   /* in zephyr\dts\arm\nordic\nrf52840.dtsi:352 */
			interrupts = < 0x15 0x1 >;     /* in zephyr\dts\arm\nordic\nrf52840.dtsi:353 */
			status = "okay";               /* in zephyr\dts\arm\nordic\nrf52840.dtsi:354 */
		};

		/* node '/soc/egu@40016000' defined in zephyr\dts\arm\nordic\nrf52840.dtsi:357 */
		egu2: swi2: egu@40016000 {
			compatible = "nordic,nrf-egu",
			             "nordic,nrf-swi"; /* in zephyr\dts\arm\nordic\nrf52840.dtsi:358 */
			reg = < 0x40016000 0x1000 >;   /* in zephyr\dts\arm\nordic\nrf52840.dtsi:359 */
			interrupts = < 0x16 0x1 >;     /* in zephyr\dts\arm\nordic\nrf52840.dtsi:360 */
			status = "okay";               /* in zephyr\dts\arm\nordic\nrf52840.dtsi:361 */
		};

		/* node '/soc/egu@40017000' defined in zephyr\dts\arm\nordic\nrf52840.dtsi:364 */
		egu3: swi3: egu@40017000 {
			compatible = "nordic,nrf-egu",
			             "nordic,nrf-swi"; /* in zephyr\dts\arm\nordic\nrf52840.dtsi:365 */
			reg = < 0x40017000 0x1000 >;   /* in zephyr\dts\arm\nordic\nrf52840.dtsi:366 */
			interrupts = < 0x17 0x1 >;     /* in zephyr\dts\arm\nordic\nrf52840.dtsi:367 */
			status = "okay";               /* in zephyr\dts\arm\nordic\nrf52840.dtsi:368 */
		};

		/* node '/soc/egu@40018000' defined in zephyr\dts\arm\nordic\nrf52840.dtsi:371 */
		egu4: swi4: egu@40018000 {
			compatible = "nordic,nrf-egu",
			             "nordic,nrf-swi"; /* in zephyr\dts\arm\nordic\nrf52840.dtsi:372 */
			reg = < 0x40018000 0x1000 >;   /* in zephyr\dts\arm\nordic\nrf52840.dtsi:373 */
			interrupts = < 0x18 0x1 >;     /* in zephyr\dts\arm\nordic\nrf52840.dtsi:374 */
			status = "okay";               /* in zephyr\dts\arm\nordic\nrf52840.dtsi:375 */
		};

		/* node '/soc/egu@40019000' defined in zephyr\dts\arm\nordic\nrf52840.dtsi:378 */
		egu5: swi5: egu@40019000 {
			compatible = "nordic,nrf-egu",
			             "nordic,nrf-swi"; /* in zephyr\dts\arm\nordic\nrf52840.dtsi:379 */
			reg = < 0x40019000 0x1000 >;   /* in zephyr\dts\arm\nordic\nrf52840.dtsi:380 */
			interrupts = < 0x19 0x1 >;     /* in zephyr\dts\arm\nordic\nrf52840.dtsi:381 */
			status = "okay";               /* in zephyr\dts\arm\nordic\nrf52840.dtsi:382 */
		};

		/* node '/soc/timer@4001a000' defined in zephyr\dts\arm\nordic\nrf52840.dtsi:385 */
		timer3: timer@4001a000 {
			compatible = "nordic,nrf-timer"; /* in zephyr\dts\arm\nordic\nrf52840.dtsi:386 */
			status = "disabled";             /* in zephyr\dts\arm\nordic\nrf52840.dtsi:387 */
			reg = < 0x4001a000 0x1000 >;     /* in zephyr\dts\arm\nordic\nrf52840.dtsi:388 */
			cc-num = < 0x6 >;                /* in zephyr\dts\arm\nordic\nrf52840.dtsi:389 */
			max-bit-width = < 0x20 >;        /* in zephyr\dts\arm\nordic\nrf52840.dtsi:390 */
			interrupts = < 0x1a 0x1 >;       /* in zephyr\dts\arm\nordic\nrf52840.dtsi:391 */
			prescaler = < 0x0 >;             /* in zephyr\dts\arm\nordic\nrf52840.dtsi:392 */
		};

		/* node '/soc/timer@4001b000' defined in zephyr\dts\arm\nordic\nrf52840.dtsi:395 */
		timer4: timer@4001b000 {
			compatible = "nordic,nrf-timer"; /* in zephyr\dts\arm\nordic\nrf52840.dtsi:396 */
			status = "disabled";             /* in zephyr\dts\arm\nordic\nrf52840.dtsi:397 */
			reg = < 0x4001b000 0x1000 >;     /* in zephyr\dts\arm\nordic\nrf52840.dtsi:398 */
			cc-num = < 0x6 >;                /* in zephyr\dts\arm\nordic\nrf52840.dtsi:399 */
			max-bit-width = < 0x20 >;        /* in zephyr\dts\arm\nordic\nrf52840.dtsi:400 */
			interrupts = < 0x1b 0x1 >;       /* in zephyr\dts\arm\nordic\nrf52840.dtsi:401 */
			prescaler = < 0x0 >;             /* in zephyr\dts\arm\nordic\nrf52840.dtsi:402 */
		};

		/* node '/soc/pwm@4001c000' defined in zephyr\dts\arm\nordic\nrf52840.dtsi:405 */
		pwm0: pwm@4001c000 {
			compatible = "nordic,nrf-pwm"; /* in zephyr\dts\arm\nordic\nrf52840.dtsi:406 */
			reg = < 0x4001c000 0x1000 >;   /* in zephyr\dts\arm\nordic\nrf52840.dtsi:407 */
			interrupts = < 0x1c 0x1 >;     /* in zephyr\dts\arm\nordic\nrf52840.dtsi:408 */
			#pwm-cells = < 0x3 >;          /* in zephyr\dts\arm\nordic\nrf52840.dtsi:410 */
			status = "okay";               /* in zephyr\boards\nordic\nrf52840dongle\nrf52840dongle_nrf52840_common.dtsi:153 */
			pinctrl-0 = < &pwm0_default >; /* in zephyr\boards\nordic\nrf52840dongle\nrf52840dongle_nrf52840_common.dtsi:154 */
			pinctrl-1 = < &pwm0_sleep >;   /* in zephyr\boards\nordic\nrf52840dongle\nrf52840dongle_nrf52840_common.dtsi:155 */
			pinctrl-names = "default",
			                "sleep";       /* in zephyr\boards\nordic\nrf52840dongle\nrf52840dongle_nrf52840_common.dtsi:156 */
			phandle = < 0x12 >;            /* in zephyr\boards\nordic\nrf52840dongle\nrf52840dongle_nrf52840_common.dtsi:52 */
		};

		/* node '/soc/pdm@4001d000' defined in zephyr\dts\arm\nordic\nrf52840.dtsi:413 */
		pdm0: pdm@4001d000 {
			compatible = "nordic,nrf-pdm"; /* in zephyr\dts\arm\nordic\nrf52840.dtsi:414 */
			reg = < 0x4001d000 0x1000 >;   /* in zephyr\dts\arm\nordic\nrf52840.dtsi:415 */
			interrupts = < 0x1d 0x1 >;     /* in zephyr\dts\arm\nordic\nrf52840.dtsi:416 */
			status = "disabled";           /* in zephyr\dts\arm\nordic\nrf52840.dtsi:417 */
		};

		/* node '/soc/acl@4001e000' defined in zephyr\dts\arm\nordic\nrf52840.dtsi:420 */
		acl: acl@4001e000 {
			compatible = "nordic,nrf-acl"; /* in zephyr\dts\arm\nordic\nrf52840.dtsi:421 */
			reg = < 0x4001e000 0x1000 >;   /* in zephyr\dts\arm\nordic\nrf52840.dtsi:422 */
			status = "okay";               /* in zephyr\dts\arm\nordic\nrf52840.dtsi:423 */
		};

		/* node '/soc/flash-controller@4001e000' defined in zephyr\dts\arm\nordic\nrf52840.dtsi:426 */
		flash_controller: flash-controller@4001e000 {
			compatible = "nordic,nrf52-flash-controller"; /* in zephyr\dts\arm\nordic\nrf52840.dtsi:427 */
			reg = < 0x4001e000 0x1000 >;                  /* in zephyr\dts\arm\nordic\nrf52840.dtsi:428 */
			partial-erase;                                /* in zephyr\dts\arm\nordic\nrf52840.dtsi:429 */
			#address-cells = < 0x1 >;                     /* in zephyr\dts\arm\nordic\nrf52840.dtsi:431 */
			#size-cells = < 0x1 >;                        /* in zephyr\dts\arm\nordic\nrf52840.dtsi:432 */

			/* node '/soc/flash-controller@4001e000/flash@0' defined in zephyr\dts\arm\nordic\nrf52840.dtsi:434 */
			flash0: flash@0 {
				compatible = "soc-nv-flash";   /* in zephyr\dts\arm\nordic\nrf52840.dtsi:435 */
				erase-block-size = < 0x1000 >; /* in zephyr\dts\arm\nordic\nrf52840.dtsi:436 */
				write-block-size = < 0x4 >;    /* in zephyr\dts\arm\nordic\nrf52840.dtsi:437 */
				reg = < 0x0 0x100000 >;        /* in zephyr\dts\arm\nordic\nrf52840_qiaa.dtsi:11 */

				/* node '/soc/flash-controller@4001e000/flash@0/partitions' defined in zephyr\boards\nordic\nrf52840dongle\nrf52840dongle_nrf52840.dts:14 */
				partitions {
					compatible = "fixed-partitions"; /* in zephyr\boards\nordic\nrf52840dongle\nrf52840dongle_nrf52840.dts:15 */
					#address-cells = < 0x1 >;        /* in zephyr\boards\nordic\nrf52840dongle\nrf52840dongle_nrf52840.dts:16 */
					#size-cells = < 0x1 >;           /* in zephyr\boards\nordic\nrf52840dongle\nrf52840dongle_nrf52840.dts:17 */

					/* node '/soc/flash-controller@4001e000/flash@0/partitions/partition@1000' defined in zephyr\boards\nordic\nrf52840dongle\nrf52840dongle_nrf52840.dts:23 */
					boot_partition: partition@1000 {
						label = "mcuboot";       /* in zephyr\boards\nordic\nrf52840dongle\nrf52840dongle_nrf52840.dts:24 */
						reg = < 0x1000 0xf000 >; /* in zephyr\boards\nordic\nrf52840dongle\nrf52840dongle_nrf52840.dts:25 */
					};

					/* node '/soc/flash-controller@4001e000/flash@0/partitions/partition@10000' defined in zephyr\boards\nordic\nrf52840dongle\nrf52840dongle_nrf52840.dts:28 */
					slot0_partition: partition@10000 {
						label = "image-0";         /* in zephyr\boards\nordic\nrf52840dongle\nrf52840dongle_nrf52840.dts:29 */
						reg = < 0x10000 0x66000 >; /* in zephyr\boards\nordic\nrf52840dongle\nrf52840dongle_nrf52840.dts:30 */
					};

					/* node '/soc/flash-controller@4001e000/flash@0/partitions/partition@76000' defined in zephyr\boards\nordic\nrf52840dongle\nrf52840dongle_nrf52840.dts:33 */
					slot1_partition: partition@76000 {
						label = "image-1";         /* in zephyr\boards\nordic\nrf52840dongle\nrf52840dongle_nrf52840.dts:34 */
						reg = < 0x76000 0x66000 >; /* in zephyr\boards\nordic\nrf52840dongle\nrf52840dongle_nrf52840.dts:35 */
					};

					/* node '/soc/flash-controller@4001e000/flash@0/partitions/partition@dc000' defined in zephyr\boards\nordic\nrf52840dongle\nrf52840dongle_nrf52840.dts:38 */
					storage_partition: partition@dc000 {
						label = "storage";        /* in zephyr\boards\nordic\nrf52840dongle\nrf52840dongle_nrf52840.dts:39 */
						reg = < 0xdc000 0x4000 >; /* in zephyr\boards\nordic\nrf52840dongle\nrf52840dongle_nrf52840.dts:40 */
					};
				};
			};
		};

		/* node '/soc/ppi@4001f000' defined in zephyr\dts\arm\nordic\nrf52840.dtsi:441 */
		ppi: ppi@4001f000 {
			compatible = "nordic,nrf-ppi"; /* in zephyr\dts\arm\nordic\nrf52840.dtsi:442 */
			reg = < 0x4001f000 0x1000 >;   /* in zephyr\dts\arm\nordic\nrf52840.dtsi:443 */
			status = "okay";               /* in zephyr\dts\arm\nordic\nrf52840.dtsi:444 */
		};

		/* node '/soc/mwu@40020000' defined in zephyr\dts\arm\nordic\nrf52840.dtsi:447 */
		mwu: mwu@40020000 {
			compatible = "nordic,nrf-mwu"; /* in zephyr\dts\arm\nordic\nrf52840.dtsi:448 */
			reg = < 0x40020000 0x1000 >;   /* in zephyr\dts\arm\nordic\nrf52840.dtsi:449 */
			status = "okay";               /* in zephyr\dts\arm\nordic\nrf52840.dtsi:450 */
		};

		/* node '/soc/pwm@40021000' defined in zephyr\dts\arm\nordic\nrf52840.dtsi:453 */
		pwm1: pwm@40021000 {
			compatible = "nordic,nrf-pwm"; /* in zephyr\dts\arm\nordic\nrf52840.dtsi:454 */
			reg = < 0x40021000 0x1000 >;   /* in zephyr\dts\arm\nordic\nrf52840.dtsi:455 */
			interrupts = < 0x21 0x1 >;     /* in zephyr\dts\arm\nordic\nrf52840.dtsi:456 */
			status = "disabled";           /* in zephyr\dts\arm\nordic\nrf52840.dtsi:457 */
			#pwm-cells = < 0x3 >;          /* in zephyr\dts\arm\nordic\nrf52840.dtsi:458 */
		};

		/* node '/soc/pwm@40022000' defined in zephyr\dts\arm\nordic\nrf52840.dtsi:461 */
		pwm2: pwm@40022000 {
			compatible = "nordic,nrf-pwm"; /* in zephyr\dts\arm\nordic\nrf52840.dtsi:462 */
			reg = < 0x40022000 0x1000 >;   /* in zephyr\dts\arm\nordic\nrf52840.dtsi:463 */
			interrupts = < 0x22 0x1 >;     /* in zephyr\dts\arm\nordic\nrf52840.dtsi:464 */
			status = "disabled";           /* in zephyr\dts\arm\nordic\nrf52840.dtsi:465 */
			#pwm-cells = < 0x3 >;          /* in zephyr\dts\arm\nordic\nrf52840.dtsi:466 */
		};

		/* node '/soc/spi@40023000' defined in zephyr\dts\arm\nordic\nrf52840.dtsi:469 */
		spi2: spi@40023000 {
			compatible = "nordic,nrf-spim"; /* in zephyr\dts\arm\nordic\nrf52840.dtsi:477 */
			#address-cells = < 0x1 >;       /* in zephyr\dts\arm\nordic\nrf52840.dtsi:478 */
			#size-cells = < 0x0 >;          /* in zephyr\dts\arm\nordic\nrf52840.dtsi:479 */
			reg = < 0x40023000 0x1000 >;    /* in zephyr\dts\arm\nordic\nrf52840.dtsi:480 */
			interrupts = < 0x23 0x1 >;      /* in zephyr\dts\arm\nordic\nrf52840.dtsi:481 */
			max-frequency = < 0x7a1200 >;   /* in zephyr\dts\arm\nordic\nrf52840.dtsi:482 */
			easydma-maxcnt-bits = < 0x10 >; /* in zephyr\dts\arm\nordic\nrf52840.dtsi:483 */
			status = "disabled";            /* in zephyr\dts\arm\nordic\nrf52840.dtsi:484 */
		};

		/* node '/soc/rtc@40024000' defined in zephyr\dts\arm\nordic\nrf52840.dtsi:487 */
		rtc2: rtc@40024000 {
			compatible = "nordic,nrf-rtc"; /* in zephyr\dts\arm\nordic\nrf52840.dtsi:488 */
			reg = < 0x40024000 0x1000 >;   /* in zephyr\dts\arm\nordic\nrf52840.dtsi:489 */
			cc-num = < 0x4 >;              /* in zephyr\dts\arm\nordic\nrf52840.dtsi:490 */
			interrupts = < 0x24 0x1 >;     /* in zephyr\dts\arm\nordic\nrf52840.dtsi:491 */
			status = "disabled";           /* in zephyr\dts\arm\nordic\nrf52840.dtsi:492 */
			clock-frequency = < 0x8000 >;  /* in zephyr\dts\arm\nordic\nrf52840.dtsi:493 */
			prescaler = < 0x1 >;           /* in zephyr\dts\arm\nordic\nrf52840.dtsi:494 */
		};

		/* node '/soc/i2s@40025000' defined in zephyr\dts\arm\nordic\nrf52840.dtsi:497 */
		i2s0: i2s@40025000 {
			compatible = "nordic,nrf-i2s"; /* in zephyr\dts\arm\nordic\nrf52840.dtsi:498 */
			#address-cells = < 0x1 >;      /* in zephyr\dts\arm\nordic\nrf52840.dtsi:499 */
			#size-cells = < 0x0 >;         /* in zephyr\dts\arm\nordic\nrf52840.dtsi:500 */
			reg = < 0x40025000 0x1000 >;   /* in zephyr\dts\arm\nordic\nrf52840.dtsi:501 */
			interrupts = < 0x25 0x1 >;     /* in zephyr\dts\arm\nordic\nrf52840.dtsi:502 */
			status = "disabled";           /* in zephyr\dts\arm\nordic\nrf52840.dtsi:503 */
		};

		/* node '/soc/usbd@40027000' defined in zephyr\dts\arm\nordic\nrf52840.dtsi:506 */
		usbd: zephyr_udc0: usbd@40027000 {
			reg = < 0x40027000 0x1000 >;    /* in zephyr\dts\arm\nordic\nrf52840.dtsi:508 */
			interrupts = < 0x27 0x1 >;      /* in zephyr\dts\arm\nordic\nrf52840.dtsi:509 */
			num-bidir-endpoints = < 0x1 >;  /* in zephyr\dts\arm\nordic\nrf52840.dtsi:510 */
			num-in-endpoints = < 0x7 >;     /* in zephyr\dts\arm\nordic\nrf52840.dtsi:511 */
			num-out-endpoints = < 0x7 >;    /* in zephyr\dts\arm\nordic\nrf52840.dtsi:512 */
			num-isoin-endpoints = < 0x1 >;  /* in zephyr\dts\arm\nordic\nrf52840.dtsi:513 */
			num-isoout-endpoints = < 0x1 >; /* in zephyr\dts\arm\nordic\nrf52840.dtsi:514 */
			compatible = "nordic,nrf-usbd"; /* in zephyr\boards\nordic\nrf52840dongle\nrf52840dongle_nrf52840_common.dtsi:185 */
			status = "okay";                /* in zephyr\boards\nordic\nrf52840dongle\nrf52840dongle_nrf52840_common.dtsi:186 */

			/* node '/soc/usbd@40027000/board_cdc_acm_uart' defined in zephyr\boards\common\usb\cdc_acm_serial.dtsi:18 */
			board_cdc_acm_uart: board_cdc_acm_uart {
				compatible = "zephyr,cdc-acm-uart"; /* in zephyr\boards\common\usb\cdc_acm_serial.dtsi:19 */
			};

			/* node '/soc/usbd@40027000/cdc_acm_uart0' defined in nrf\samples\bluetooth\central_uart_test\app.overlay:9 */
			cdc_acm_uart0: cdc_acm_uart0 {
				compatible = "zephyr,cdc-acm-uart"; /* in nrf\samples\bluetooth\central_uart_test\app.overlay:10 */
			};
		};

		/* node '/soc/uart@40028000' defined in zephyr\dts\arm\nordic\nrf52840.dtsi:518 */
		uart1: uart@40028000 {
			compatible = "nordic,nrf-uarte"; /* in zephyr\dts\arm\nordic\nrf52840.dtsi:519 */
			reg = < 0x40028000 0x1000 >;     /* in zephyr\dts\arm\nordic\nrf52840.dtsi:520 */
			interrupts = < 0x28 0x1 >;       /* in zephyr\dts\arm\nordic\nrf52840.dtsi:521 */
			status = "disabled";             /* in zephyr\dts\arm\nordic\nrf52840.dtsi:522 */
		};

		/* node '/soc/qspi@40029000' defined in zephyr\dts\arm\nordic\nrf52840.dtsi:525 */
		qspi: qspi@40029000 {
			compatible = "nordic,nrf-qspi"; /* in zephyr\dts\arm\nordic\nrf52840.dtsi:526 */
			#address-cells = < 0x1 >;       /* in zephyr\dts\arm\nordic\nrf52840.dtsi:527 */
			#size-cells = < 0x0 >;          /* in zephyr\dts\arm\nordic\nrf52840.dtsi:528 */
			reg = < 0x40029000 0x1000 >,
			      < 0x12000000 0x8000000 >; /* in zephyr\dts\arm\nordic\nrf52840.dtsi:529 */
			reg-names = "qspi",
			            "qspi_mm";          /* in zephyr\dts\arm\nordic\nrf52840.dtsi:530 */
			interrupts = < 0x29 0x1 >;      /* in zephyr\dts\arm\nordic\nrf52840.dtsi:531 */
			status = "disabled";            /* in zephyr\dts\arm\nordic\nrf52840.dtsi:532 */
		};

		/* node '/soc/pwm@4002d000' defined in zephyr\dts\arm\nordic\nrf52840.dtsi:535 */
		pwm3: pwm@4002d000 {
			compatible = "nordic,nrf-pwm"; /* in zephyr\dts\arm\nordic\nrf52840.dtsi:536 */
			reg = < 0x4002d000 0x1000 >;   /* in zephyr\dts\arm\nordic\nrf52840.dtsi:537 */
			interrupts = < 0x2d 0x1 >;     /* in zephyr\dts\arm\nordic\nrf52840.dtsi:538 */
			status = "disabled";           /* in zephyr\dts\arm\nordic\nrf52840.dtsi:539 */
			#pwm-cells = < 0x3 >;          /* in zephyr\dts\arm\nordic\nrf52840.dtsi:540 */
		};

		/* node '/soc/spi@4002f000' defined in zephyr\dts\arm\nordic\nrf52840.dtsi:543 */
		spi3: spi@4002f000 {
			compatible = "nordic,nrf-spim"; /* in zephyr\dts\arm\nordic\nrf52840.dtsi:544 */
			#address-cells = < 0x1 >;       /* in zephyr\dts\arm\nordic\nrf52840.dtsi:545 */
			#size-cells = < 0x0 >;          /* in zephyr\dts\arm\nordic\nrf52840.dtsi:546 */
			reg = < 0x4002f000 0x1000 >;    /* in zephyr\dts\arm\nordic\nrf52840.dtsi:547 */
			interrupts = < 0x2f 0x1 >;      /* in zephyr\dts\arm\nordic\nrf52840.dtsi:548 */
			max-frequency = < 0x1e84800 >;  /* in zephyr\dts\arm\nordic\nrf52840.dtsi:549 */
			easydma-maxcnt-bits = < 0x10 >; /* in zephyr\dts\arm\nordic\nrf52840.dtsi:550 */
			rx-delay-supported;             /* in zephyr\dts\arm\nordic\nrf52840.dtsi:551 */
			rx-delay = < 0x2 >;             /* in zephyr\dts\arm\nordic\nrf52840.dtsi:552 */
			status = "disabled";            /* in zephyr\dts\arm\nordic\nrf52840.dtsi:553 */
		};

		/* node '/soc/gpio@50000000' defined in zephyr\dts\arm\nordic\nrf52840.dtsi:556 */
		gpio0: gpio@50000000 {
			compatible = "nordic,nrf-gpio";              /* in zephyr\dts\arm\nordic\nrf52840.dtsi:557 */
			gpio-controller;                             /* in zephyr\dts\arm\nordic\nrf52840.dtsi:558 */
			reg = < 0x50000000 0x200 0x50000500 0x300 >; /* in zephyr\dts\arm\nordic\nrf52840.dtsi:559 */
			#gpio-cells = < 0x2 >;                       /* in zephyr\dts\arm\nordic\nrf52840.dtsi:561 */
			port = < 0x0 >;                              /* in zephyr\dts\arm\nordic\nrf52840.dtsi:563 */
			gpiote-instance = < &gpiote >;               /* in zephyr\dts\arm\nordic\nrf52840.dtsi:564 */
			status = "okay";                             /* in zephyr\boards\nordic\nrf52840dongle\nrf52840dongle_nrf52840_common.dtsi:119 */
			phandle = < 0x10 >;                          /* in zephyr\boards\nordic\nrf52840dongle\nrf52840dongle_nrf52840_common.dtsi:28 */
		};

		/* node '/soc/gpio@50000300' defined in zephyr\dts\arm\nordic\nrf52840.dtsi:567 */
		gpio1: gpio@50000300 {
			compatible = "nordic,nrf-gpio";              /* in zephyr\dts\arm\nordic\nrf52840.dtsi:568 */
			gpio-controller;                             /* in zephyr\dts\arm\nordic\nrf52840.dtsi:569 */
			reg = < 0x50000300 0x200 0x50000800 0x300 >; /* in zephyr\dts\arm\nordic\nrf52840.dtsi:570 */
			#gpio-cells = < 0x2 >;                       /* in zephyr\dts\arm\nordic\nrf52840.dtsi:572 */
			ngpios = < 0x10 >;                           /* in zephyr\dts\arm\nordic\nrf52840.dtsi:573 */
			port = < 0x1 >;                              /* in zephyr\dts\arm\nordic\nrf52840.dtsi:575 */
			gpiote-instance = < &gpiote >;               /* in zephyr\dts\arm\nordic\nrf52840.dtsi:576 */
			status = "okay";                             /* in zephyr\boards\nordic\nrf52840dongle\nrf52840dongle_nrf52840_common.dtsi:123 */
			phandle = < 0x11 >;                          /* in zephyr\boards\nordic\nrf52840dongle\nrf52840dongle_nrf52840_common.dtsi:38 */
		};

		/* node '/soc/crypto@5002a000' defined in zephyr\dts\arm\nordic\nrf52840.dtsi:579 */
		cryptocell: crypto@5002a000 {
			compatible = "arm,cryptocell-310"; /* in zephyr\dts\arm\nordic\nrf52840.dtsi:580 */
			reg = < 0x5002a000 0x1000 >,
			      < 0x5002b000 0x1000 >;       /* in zephyr\dts\arm\nordic\nrf52840.dtsi:581 */
			reg-names = "wrapper",
			            "core";                /* in zephyr\dts\arm\nordic\nrf52840.dtsi:582 */
			interrupts = < 0x2a 0x1 >;         /* in zephyr\dts\arm\nordic\nrf52840.dtsi:583 */
			status = "okay";                   /* in zephyr\dts\arm\nordic\nrf52840.dtsi:584 */
		};
	};

	/* node '/pin-controller' defined in zephyr\dts\vendor\nordic\nrf_common.dtsi:26 */
	pinctrl: pin-controller {
		compatible = "nordic,nrf-pinctrl"; /* in zephyr\dts\vendor\nordic\nrf_common.dtsi:31 */

		/* node '/pin-controller/uart0_default' defined in zephyr\boards\nordic\nrf52840dongle\nrf52840dongle_nrf52840-pinctrl.dtsi:7 */
		uart0_default: uart0_default {
			phandle = < 0x2 >; /* in zephyr\boards\nordic\nrf52840dongle\nrf52840dongle_nrf52840_common.dtsi:130 */

			/* node '/pin-controller/uart0_default/group1' defined in zephyr\boards\nordic\nrf52840dongle\nrf52840dongle_nrf52840-pinctrl.dtsi:8 */
			group1 {
				psels = < 0x14 >,
				        < 0x2000011 >; /* in zephyr\boards\nordic\nrf52840dongle\nrf52840dongle_nrf52840-pinctrl.dtsi:9 */
			};

			/* node '/pin-controller/uart0_default/group2' defined in zephyr\boards\nordic\nrf52840dongle\nrf52840dongle_nrf52840-pinctrl.dtsi:13 */
			group2 {
				psels = < 0x1000018 >,
				        < 0x3000016 >; /* in zephyr\boards\nordic\nrf52840dongle\nrf52840dongle_nrf52840-pinctrl.dtsi:14 */
				bias-pull-up;          /* in zephyr\boards\nordic\nrf52840dongle\nrf52840dongle_nrf52840-pinctrl.dtsi:16 */
			};
		};

		/* node '/pin-controller/uart0_sleep' defined in zephyr\boards\nordic\nrf52840dongle\nrf52840dongle_nrf52840-pinctrl.dtsi:20 */
		uart0_sleep: uart0_sleep {
			phandle = < 0x3 >; /* in zephyr\boards\nordic\nrf52840dongle\nrf52840dongle_nrf52840_common.dtsi:131 */

			/* node '/pin-controller/uart0_sleep/group1' defined in zephyr\boards\nordic\nrf52840dongle\nrf52840dongle_nrf52840-pinctrl.dtsi:21 */
			group1 {
				psels = < 0x1000018 >,
				        < 0x2000011 >,
				        < 0x3000016 >; /* in zephyr\boards\nordic\nrf52840dongle\nrf52840dongle_nrf52840-pinctrl.dtsi:22 */
				low-power-enable;      /* in zephyr\boards\nordic\nrf52840dongle\nrf52840dongle_nrf52840-pinctrl.dtsi:25 */
			};

			/* node '/pin-controller/uart0_sleep/group2' defined in zephyr\boards\nordic\nrf52840dongle\nrf52840dongle_nrf52840-pinctrl.dtsi:28 */
			group2 {
				psels = < 0x14 >; /* in zephyr\boards\nordic\nrf52840dongle\nrf52840dongle_nrf52840-pinctrl.dtsi:29 */
				low-power-enable; /* in zephyr\boards\nordic\nrf52840dongle\nrf52840dongle_nrf52840-pinctrl.dtsi:30 */
				bias-pull-up;     /* in zephyr\boards\nordic\nrf52840dongle\nrf52840dongle_nrf52840-pinctrl.dtsi:31 */
			};
		};

		/* node '/pin-controller/i2c0_default' defined in zephyr\boards\nordic\nrf52840dongle\nrf52840dongle_nrf52840-pinctrl.dtsi:35 */
		i2c0_default: i2c0_default {
			phandle = < 0x4 >; /* in zephyr\boards\nordic\nrf52840dongle\nrf52840dongle_nrf52840_common.dtsi:138 */

			/* node '/pin-controller/i2c0_default/group1' defined in zephyr\boards\nordic\nrf52840dongle\nrf52840dongle_nrf52840-pinctrl.dtsi:36 */
			group1 {
				psels = < 0xc00001a >,
				        < 0xb00001b >; /* in zephyr\boards\nordic\nrf52840dongle\nrf52840dongle_nrf52840-pinctrl.dtsi:37 */
			};
		};

		/* node '/pin-controller/i2c0_sleep' defined in zephyr\boards\nordic\nrf52840dongle\nrf52840dongle_nrf52840-pinctrl.dtsi:42 */
		i2c0_sleep: i2c0_sleep {
			phandle = < 0x5 >; /* in zephyr\boards\nordic\nrf52840dongle\nrf52840dongle_nrf52840_common.dtsi:139 */

			/* node '/pin-controller/i2c0_sleep/group1' defined in zephyr\boards\nordic\nrf52840dongle\nrf52840dongle_nrf52840-pinctrl.dtsi:43 */
			group1 {
				psels = < 0xc00001a >,
				        < 0xb00001b >; /* in zephyr\boards\nordic\nrf52840dongle\nrf52840dongle_nrf52840-pinctrl.dtsi:44 */
				low-power-enable;      /* in zephyr\boards\nordic\nrf52840dongle\nrf52840dongle_nrf52840-pinctrl.dtsi:46 */
			};
		};

		/* node '/pin-controller/i2c1_default' defined in zephyr\boards\nordic\nrf52840dongle\nrf52840dongle_nrf52840-pinctrl.dtsi:50 */
		i2c1_default: i2c1_default {
			phandle = < 0x8 >; /* in zephyr\boards\nordic\nrf52840dongle\nrf52840dongle_nrf52840_common.dtsi:147 */

			/* node '/pin-controller/i2c1_default/group1' defined in zephyr\boards\nordic\nrf52840dongle\nrf52840dongle_nrf52840-pinctrl.dtsi:51 */
			group1 {
				psels = < 0xc00001e >,
				        < 0xb00001f >; /* in zephyr\boards\nordic\nrf52840dongle\nrf52840dongle_nrf52840-pinctrl.dtsi:52 */
			};
		};

		/* node '/pin-controller/i2c1_sleep' defined in zephyr\boards\nordic\nrf52840dongle\nrf52840dongle_nrf52840-pinctrl.dtsi:57 */
		i2c1_sleep: i2c1_sleep {
			phandle = < 0x9 >; /* in zephyr\boards\nordic\nrf52840dongle\nrf52840dongle_nrf52840_common.dtsi:148 */

			/* node '/pin-controller/i2c1_sleep/group1' defined in zephyr\boards\nordic\nrf52840dongle\nrf52840dongle_nrf52840-pinctrl.dtsi:58 */
			group1 {
				psels = < 0xc00001e >,
				        < 0xb00001f >; /* in zephyr\boards\nordic\nrf52840dongle\nrf52840dongle_nrf52840-pinctrl.dtsi:59 */
				low-power-enable;      /* in zephyr\boards\nordic\nrf52840dongle\nrf52840dongle_nrf52840-pinctrl.dtsi:61 */
			};
		};

		/* node '/pin-controller/pwm0_default' defined in zephyr\boards\nordic\nrf52840dongle\nrf52840dongle_nrf52840-pinctrl.dtsi:65 */
		pwm0_default: pwm0_default {
			phandle = < 0xc >; /* in zephyr\boards\nordic\nrf52840dongle\nrf52840dongle_nrf52840_common.dtsi:154 */

			/* node '/pin-controller/pwm0_default/group1' defined in zephyr\boards\nordic\nrf52840dongle\nrf52840dongle_nrf52840-pinctrl.dtsi:66 */
			group1 {
				psels = < 0x16000008 >,
				        < 0x17000029 >,
				        < 0x1800000c >; /* in zephyr\boards\nordic\nrf52840dongle\nrf52840dongle_nrf52840-pinctrl.dtsi:67 */
				nordic,invert;          /* in zephyr\boards\nordic\nrf52840dongle\nrf52840dongle_nrf52840-pinctrl.dtsi:70 */
			};
		};

		/* node '/pin-controller/pwm0_sleep' defined in zephyr\boards\nordic\nrf52840dongle\nrf52840dongle_nrf52840-pinctrl.dtsi:74 */
		pwm0_sleep: pwm0_sleep {
			phandle = < 0xd >; /* in zephyr\boards\nordic\nrf52840dongle\nrf52840dongle_nrf52840_common.dtsi:155 */

			/* node '/pin-controller/pwm0_sleep/group1' defined in zephyr\boards\nordic\nrf52840dongle\nrf52840dongle_nrf52840-pinctrl.dtsi:75 */
			group1 {
				psels = < 0x16000008 >,
				        < 0x17000029 >,
				        < 0x1800000c >; /* in zephyr\boards\nordic\nrf52840dongle\nrf52840dongle_nrf52840-pinctrl.dtsi:76 */
				low-power-enable;       /* in zephyr\boards\nordic\nrf52840dongle\nrf52840dongle_nrf52840-pinctrl.dtsi:79 */
			};
		};

		/* node '/pin-controller/spi0_default' defined in zephyr\boards\nordic\nrf52840dongle\nrf52840dongle_nrf52840-pinctrl.dtsi:83 */
		spi0_default: spi0_default {
			phandle = < 0x6 >; /* in zephyr\boards\nordic\nrf52840dongle\nrf52840dongle_nrf52840_common.dtsi:167 */

			/* node '/pin-controller/spi0_default/group1' defined in zephyr\boards\nordic\nrf52840dongle\nrf52840dongle_nrf52840-pinctrl.dtsi:84 */
			group1 {
				psels = < 0x400001b >,
				        < 0x500001a >,
				        < 0x600002a >; /* in zephyr\boards\nordic\nrf52840dongle\nrf52840dongle_nrf52840-pinctrl.dtsi:85 */
			};
		};

		/* node '/pin-controller/spi0_sleep' defined in zephyr\boards\nordic\nrf52840dongle\nrf52840dongle_nrf52840-pinctrl.dtsi:91 */
		spi0_sleep: spi0_sleep {
			phandle = < 0x7 >; /* in zephyr\boards\nordic\nrf52840dongle\nrf52840dongle_nrf52840_common.dtsi:168 */

			/* node '/pin-controller/spi0_sleep/group1' defined in zephyr\boards\nordic\nrf52840dongle\nrf52840dongle_nrf52840-pinctrl.dtsi:92 */
			group1 {
				psels = < 0x400001b >,
				        < 0x500001a >,
				        < 0x600002a >; /* in zephyr\boards\nordic\nrf52840dongle\nrf52840dongle_nrf52840-pinctrl.dtsi:93 */
				low-power-enable;      /* in zephyr\boards\nordic\nrf52840dongle\nrf52840dongle_nrf52840-pinctrl.dtsi:96 */
			};
		};

		/* node '/pin-controller/spi1_default' defined in zephyr\boards\nordic\nrf52840dongle\nrf52840dongle_nrf52840-pinctrl.dtsi:100 */
		spi1_default: spi1_default {
			phandle = < 0xa >; /* in zephyr\boards\nordic\nrf52840dongle\nrf52840dongle_nrf52840_common.dtsi:175 */

			/* node '/pin-controller/spi1_default/group1' defined in zephyr\boards\nordic\nrf52840dongle\nrf52840dongle_nrf52840-pinctrl.dtsi:101 */
			group1 {
				psels = < 0x400001f >,
				        < 0x500001e >,
				        < 0x600002d >; /* in zephyr\boards\nordic\nrf52840dongle\nrf52840dongle_nrf52840-pinctrl.dtsi:102 */
			};
		};

		/* node '/pin-controller/spi1_sleep' defined in zephyr\boards\nordic\nrf52840dongle\nrf52840dongle_nrf52840-pinctrl.dtsi:108 */
		spi1_sleep: spi1_sleep {
			phandle = < 0xb >; /* in zephyr\boards\nordic\nrf52840dongle\nrf52840dongle_nrf52840_common.dtsi:176 */

			/* node '/pin-controller/spi1_sleep/group1' defined in zephyr\boards\nordic\nrf52840dongle\nrf52840dongle_nrf52840-pinctrl.dtsi:109 */
			group1 {
				psels = < 0x400001f >,
				        < 0x500001e >,
				        < 0x600002d >; /* in zephyr\boards\nordic\nrf52840dongle\nrf52840dongle_nrf52840-pinctrl.dtsi:110 */
				low-power-enable;      /* in zephyr\boards\nordic\nrf52840dongle\nrf52840dongle_nrf52840-pinctrl.dtsi:113 */
			};
		};
	};

	/* node '/entropy_bt_hci' defined in zephyr\dts\vendor\nordic\nrf_common.dtsi:34 */
	rng_hci: entropy_bt_hci {
		compatible = "zephyr,bt-hci-entropy"; /* in zephyr\dts\vendor\nordic\nrf_common.dtsi:35 */
		status = "disabled";                  /* in zephyr\dts\vendor\nordic\nrf_common.dtsi:36 */
	};

	/* node '/sw-pwm' defined in zephyr\dts\vendor\nordic\nrf_common.dtsi:39 */
	sw_pwm: sw-pwm {
		compatible = "nordic,nrf-sw-pwm"; /* in zephyr\dts\vendor\nordic\nrf_common.dtsi:40 */
		status = "disabled";              /* in zephyr\dts\vendor\nordic\nrf_common.dtsi:41 */
		generator = < &timer1 >;          /* in zephyr\dts\vendor\nordic\nrf_common.dtsi:42 */
		clock-prescaler = < 0x0 >;        /* in zephyr\dts\vendor\nordic\nrf_common.dtsi:43 */
		#pwm-cells = < 0x3 >;             /* in zephyr\dts\vendor\nordic\nrf_common.dtsi:44 */
	};

	/* node '/cpus' defined in zephyr\dts\arm\nordic\nrf52840.dtsi:19 */
	cpus {
		#address-cells = < 0x1 >; /* in zephyr\dts\arm\nordic\nrf52840.dtsi:20 */
		#size-cells = < 0x0 >;    /* in zephyr\dts\arm\nordic\nrf52840.dtsi:21 */

		/* node '/cpus/cpu@0' defined in zephyr\dts\arm\nordic\nrf52840.dtsi:23 */
		cpu@0 {
			device_type = "cpu";           /* in zephyr\dts\arm\nordic\nrf52840.dtsi:24 */
			compatible = "arm,cortex-m4f"; /* in zephyr\dts\arm\nordic\nrf52840.dtsi:25 */
			reg = < 0x0 >;                 /* in zephyr\dts\arm\nordic\nrf52840.dtsi:26 */
			#address-cells = < 0x1 >;      /* in zephyr\dts\arm\nordic\nrf52840.dtsi:27 */
			#size-cells = < 0x1 >;         /* in zephyr\dts\arm\nordic\nrf52840.dtsi:28 */

			/* node '/cpus/cpu@0/itm@e0000000' defined in zephyr\dts\arm\nordic\nrf52840.dtsi:30 */
			itm: itm@e0000000 {
				compatible = "arm,armv7m-itm";     /* in zephyr\dts\arm\nordic\nrf52840.dtsi:31 */
				reg = < 0xe0000000 0x1000 >;       /* in zephyr\dts\arm\nordic\nrf52840.dtsi:32 */
				swo-ref-frequency = < 0x1e84800 >; /* in zephyr\dts\arm\nordic\nrf52840.dtsi:33 */
			};
		};
	};

	/* node '/clocks' defined in zephyr\dts\arm\nordic\nrf52840.dtsi:38 */
	clocks {

		/* node '/clocks/hfxo' defined in zephyr\dts\arm\nordic\nrf52840.dtsi:39 */
		hfxo: hfxo {
			compatible = "nordic,nrf52-hfxo"; /* in zephyr\dts\arm\nordic\nrf52840.dtsi:40 */
			clock-frequency = < 0x3d09000 >;  /* in zephyr\dts\arm\nordic\nrf52840.dtsi:41 */
			startup-time-us = < 0x578 >;      /* in zephyr\dts\arm\nordic\nrf52840.dtsi:42 */
			#clock-cells = < 0x0 >;           /* in zephyr\dts\arm\nordic\nrf52840.dtsi:43 */
		};
	};

	/* node '/leds' defined in zephyr\boards\nordic\nrf52840dongle\nrf52840dongle_nrf52840_common.dtsi:24 */
	leds {
		compatible = "gpio-leds"; /* in zephyr\boards\nordic\nrf52840dongle\nrf52840dongle_nrf52840_common.dtsi:25 */

		/* node '/leds/led_0' defined in zephyr\boards\nordic\nrf52840dongle\nrf52840dongle_nrf52840_common.dtsi:27 */
		led0_green: led_0 {
			gpios = < &gpio0 0x6 0x1 >; /* in zephyr\boards\nordic\nrf52840dongle\nrf52840dongle_nrf52840_common.dtsi:28 */
			label = "Green LED 0";      /* in zephyr\boards\nordic\nrf52840dongle\nrf52840dongle_nrf52840_common.dtsi:29 */
		};

		/* node '/leds/led_1' defined in zephyr\boards\nordic\nrf52840dongle\nrf52840dongle_nrf52840_common.dtsi:32 */
		led1_red: led_1 {
			gpios = < &gpio0 0x8 0x1 >; /* in zephyr\boards\nordic\nrf52840dongle\nrf52840dongle_nrf52840_common.dtsi:33 */
			label = "Red LED 1";        /* in zephyr\boards\nordic\nrf52840dongle\nrf52840dongle_nrf52840_common.dtsi:34 */
		};

		/* node '/leds/led_2' defined in zephyr\boards\nordic\nrf52840dongle\nrf52840dongle_nrf52840_common.dtsi:37 */
		led1_green: led_2 {
			gpios = < &gpio1 0x9 0x1 >; /* in zephyr\boards\nordic\nrf52840dongle\nrf52840dongle_nrf52840_common.dtsi:38 */
			label = "Green LED 1";      /* in zephyr\boards\nordic\nrf52840dongle\nrf52840dongle_nrf52840_common.dtsi:39 */
		};

		/* node '/leds/led_3' defined in zephyr\boards\nordic\nrf52840dongle\nrf52840dongle_nrf52840_common.dtsi:42 */
		led1_blue: led_3 {
			gpios = < &gpio0 0xc 0x1 >; /* in zephyr\boards\nordic\nrf52840dongle\nrf52840dongle_nrf52840_common.dtsi:43 */
			label = "Blue LED 1";       /* in zephyr\boards\nordic\nrf52840dongle\nrf52840dongle_nrf52840_common.dtsi:44 */
		};
	};

	/* node '/pwmleds' defined in zephyr\boards\nordic\nrf52840dongle\nrf52840dongle_nrf52840_common.dtsi:48 */
	pwmleds {
		compatible = "pwm-leds"; /* in zephyr\boards\nordic\nrf52840dongle\nrf52840dongle_nrf52840_common.dtsi:49 */

		/* node '/pwmleds/pwm_led_0' defined in zephyr\boards\nordic\nrf52840dongle\nrf52840dongle_nrf52840_common.dtsi:51 */
		red_pwm_led: pwm_led_0 {
			pwms = < &pwm0 0x0 0x1312d00 0x1 >; /* in zephyr\boards\nordic\nrf52840dongle\nrf52840dongle_nrf52840_common.dtsi:52 */
		};

		/* node '/pwmleds/pwm_led_1' defined in zephyr\boards\nordic\nrf52840dongle\nrf52840dongle_nrf52840_common.dtsi:55 */
		green_pwm_led: pwm_led_1 {
			pwms = < &pwm0 0x1 0x1312d00 0x1 >; /* in zephyr\boards\nordic\nrf52840dongle\nrf52840dongle_nrf52840_common.dtsi:56 */
		};

		/* node '/pwmleds/pwm_led_2' defined in zephyr\boards\nordic\nrf52840dongle\nrf52840dongle_nrf52840_common.dtsi:59 */
		blue_pwm_led: pwm_led_2 {
			pwms = < &pwm0 0x2 0x1312d00 0x1 >; /* in zephyr\boards\nordic\nrf52840dongle\nrf52840dongle_nrf52840_common.dtsi:60 */
		};
	};

	/* node '/buttons' defined in zephyr\boards\nordic\nrf52840dongle\nrf52840dongle_nrf52840_common.dtsi:64 */
	buttons {
		compatible = "gpio-keys"; /* in zephyr\boards\nordic\nrf52840dongle\nrf52840dongle_nrf52840_common.dtsi:65 */

		/* node '/buttons/button_0' defined in zephyr\boards\nordic\nrf52840dongle\nrf52840dongle_nrf52840_common.dtsi:67 */
		button0: button_0 {
			gpios = < &gpio1 0x6 0x11 >;    /* in zephyr\boards\nordic\nrf52840dongle\nrf52840dongle_nrf52840_common.dtsi:68 */
			label = "Push button switch 0"; /* in zephyr\boards\nordic\nrf52840dongle\nrf52840dongle_nrf52840_common.dtsi:69 */
			zephyr,code = < 0xb >;          /* in zephyr\boards\nordic\nrf52840dongle\nrf52840dongle_nrf52840_common.dtsi:70 */
		};
	};
};
